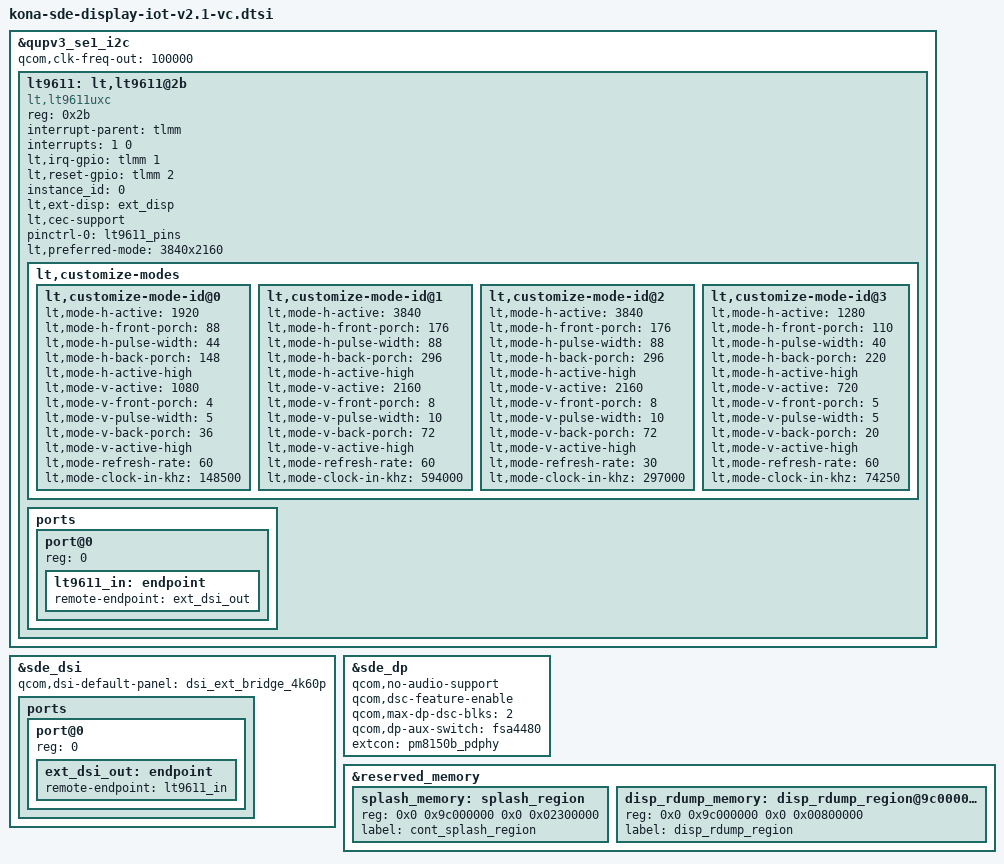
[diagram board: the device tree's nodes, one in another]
#include "kona-sde-display.dtsi"

&qupv3_se1_i2c {
	status = "ok";
	qcom,clk-freq-out = <100000>;
	lt9611: lt,lt9611@2b {
		compatible = "lt,lt9611uxc";
		reg = <0x2b>;
		interrupt-parent = <&tlmm>;
		interrupts = <1 0>;
		interrupt-names = "lt_irq";
		lt,irq-gpio = <&tlmm 1 0x0>;
		lt,reset-gpio = <&tlmm 2 0x0>;
		instance_id = <0>;

		lt,ext-disp = <&ext_disp>;
		lt,cec-support;

		pinctrl-names = "default";
		pinctrl-0 = <&lt9611_pins>;

		lt,preferred-mode = "3840x2160";

		lt,customize-modes {
			lt,customize-mode-id@0 {
				lt,mode-h-active = <1920>;
				lt,mode-h-front-porch = <88>;
				lt,mode-h-pulse-width = <44>;
				lt,mode-h-back-porch = <148>;
				lt,mode-h-active-high;
				lt,mode-v-active = <1080>;
				lt,mode-v-front-porch = <4>;
				lt,mode-v-pulse-width = <5>;
				lt,mode-v-back-porch = <36>;
				lt,mode-v-active-high;
				lt,mode-refresh-rate = <60>;
				lt,mode-clock-in-khz = <148500>;
			};


			lt,customize-mode-id@1 {
				lt,mode-h-active = <3840>;
				lt,mode-h-front-porch = <176>;
				lt,mode-h-pulse-width = <88>;
				lt,mode-h-back-porch = <296>;
				lt,mode-h-active-high;
				lt,mode-v-active = <2160>;
				lt,mode-v-front-porch = <8>;
				lt,mode-v-pulse-width = <10>;
				lt,mode-v-back-porch = <72>;
				lt,mode-v-active-high;
				lt,mode-refresh-rate = <60>;
				lt,mode-clock-in-khz = <594000>;
			};


			lt,customize-mode-id@2 {
				lt,mode-h-active = <3840>;
				lt,mode-h-front-porch = <176>;
				lt,mode-h-pulse-width = <88>;
				lt,mode-h-back-porch = <296>;
				lt,mode-h-active-high;
				lt,mode-v-active = <2160>;
				lt,mode-v-front-porch = <8>;
				lt,mode-v-pulse-width = <10>;
				lt,mode-v-back-porch = <72>;
				lt,mode-v-active-high;
				lt,mode-refresh-rate = <30>;
				lt,mode-clock-in-khz = <297000>;
			};


			lt,customize-mode-id@3 {
				lt,mode-h-active = <1280>;
				lt,mode-h-front-porch = <110>;
				lt,mode-h-pulse-width = <40>;
				lt,mode-h-back-porch = <220>;
				lt,mode-h-active-high;
				lt,mode-v-active = <720>;
				lt,mode-v-front-porch = <5>;
				lt,mode-v-pulse-width = <5>;
				lt,mode-v-back-porch = <20>;
				lt,mode-v-active-high;
				lt,mode-refresh-rate = <60>;
				lt,mode-clock-in-khz = <74250>;
			};
		};

		ports {
			#address-cells = <1>;
			#size-cells = <0>;

			port@0 {
				reg = <0>;
				lt9611_in: endpoint {
				   remote-endpoint = <&ext_dsi_out>;
				   };
			};
		};
	};
};

&sde_dsi {
	qcom,dsi-default-panel = <&dsi_ext_bridge_4k60p>;

	ports {
		#address-cells = <1>;
		#size-cells = <0>;

		port@0 {
			reg = <0>;
			ext_dsi_out: endpoint {
				 remote-endpoint = <&lt9611_in>;
			 };
		};
	};
};

&sde_dp {
	qcom,no-audio-support;
	qcom,dsc-feature-enable;
	qcom,max-dp-dsc-blks = <2>;
	qcom,dp-aux-switch = <&fsa4480>;
	extcon = <&pm8150b_pdphy>;
};

&reserved_memory {
	splash_memory: splash_region {
		reg = <0x0 0x9c000000 0x0 0x02300000>;
		label = "cont_splash_region";
	};

	disp_rdump_memory: disp_rdump_region@9c000000 {
		reg = <0x0 0x9c000000 0x0 0x00800000>;
		label = "disp_rdump_region";
	};
};

